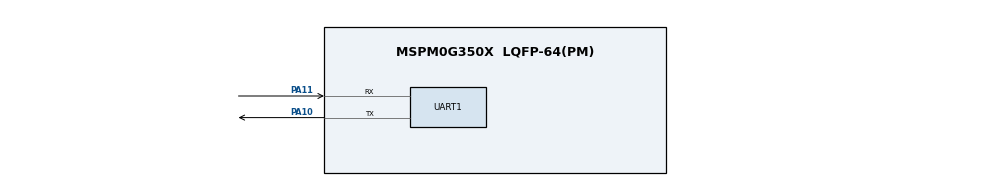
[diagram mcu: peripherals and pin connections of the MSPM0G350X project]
/**
 * @cliArgs --device "MSPM0G350X" --part "Default" --package "LQFP-64(PM)" --product "mspm0_sdk@2.05.01.00"
 * @versions {"tool":"1.24.1+4189"}
 */
scripting.excludeFromBuild("device_linker.lds");
scripting.excludeFromBuild("device.opt");
scripting.excludeFromBuild("device.lds.genlibs");
scripting.excludeFromBuild("Event.dot");

/**
 * Import the modules used in this configuration.
 */
const GPIO          = scripting.addModule("/ti/driverlib/GPIO", {}, false);
const GPIO1         = GPIO.addInstance();
const SYSCTL        = scripting.addModule("/ti/driverlib/SYSCTL");
const UART          = scripting.addModule("/ti/driverlib/UART", {}, false);
const UART1         = UART.addInstance();
const ProjectConfig = scripting.addModule("/ti/project_config/ProjectConfig");

/**
 * Write custom configuration values to the imported modules.
 */
const pinFunction3     = system.clockTree["HFCLKEXT"];
pinFunction3.inputFreq = 40;

GPIO1.$name                          = "GPIO_GRP_0";
GPIO1.associatedPins[0].$name        = "LD0";
GPIO1.associatedPins[0].assignedPort = "PORTB";
GPIO1.associatedPins[0].assignedPin  = "22";

const Board = scripting.addModule("/ti/driverlib/Board", {}, false);

SYSCTL.clockTreeEn = true;

UART1.$name                    = "UART_0";
UART1.profile                  = "CONFIG_PROFILE_1";
UART1.peripheral.$assign       = "UART0";
UART1.peripheral.rxPin.$assign = "PA11";
UART1.peripheral.txPin.$assign = "PA10";
UART1.txPinConfig.$name        = "ti_driverlib_gpio_GPIOPinGeneric0";
UART1.rxPinConfig.$name        = "ti_driverlib_gpio_GPIOPinGeneric1";

ProjectConfig.compiler = "gcc";

/**
 * Pinmux solution for unlocked pins/peripherals. This ensures that minor changes to the automatic solver in a future
 * version of the tool will not impact the pinmux you originally saw.  These lines can be completely deleted in order to
 * re-solve from scratch.
 */
GPIO1.associatedPins[0].pin.$suggestSolution = "PB22";
Board.peripheral.$suggestSolution            = "DEBUGSS";
Board.peripheral.swclkPin.$suggestSolution   = "PA20";
Board.peripheral.swdioPin.$suggestSolution   = "PA19";
